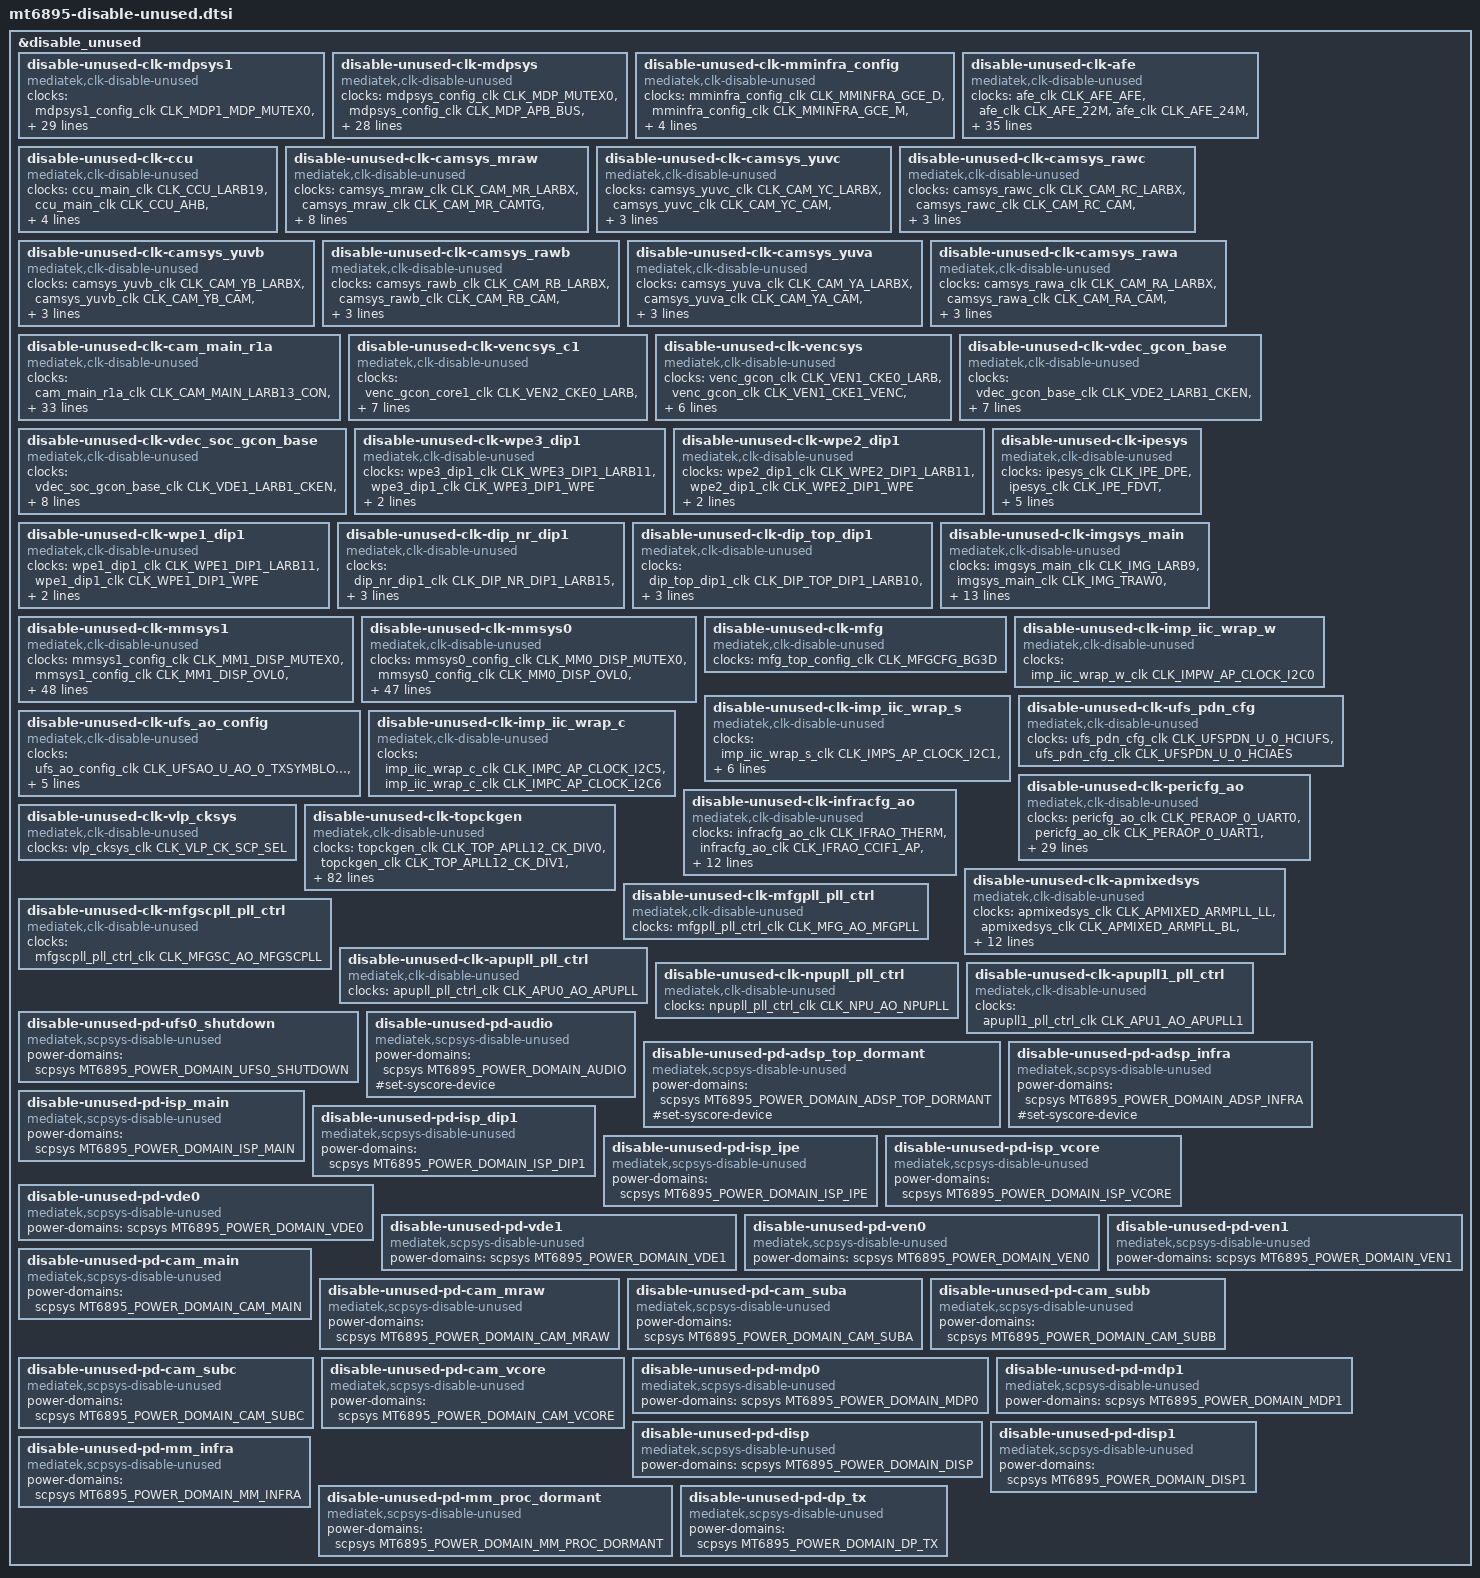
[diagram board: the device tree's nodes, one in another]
// SPDX-License-Identifier: (GPL-2.0 OR MIT)
/*
 * Copyright (C) 2021 MediaTek Inc.
 * Author: Ren-Ting Wang <ren-ting.wang@mediatek.com>
 */

&disable_unused {
	status = "okay";
	disable-unused-clk-mdpsys1 {
		compatible = "mediatek,clk-disable-unused";
		clocks =
			<&mdpsys1_config_clk CLK_MDP1_MDP_MUTEX0>,
			<&mdpsys1_config_clk CLK_MDP1_APB_BUS>,
			<&mdpsys1_config_clk CLK_MDP1_SMI0>,
			<&mdpsys1_config_clk CLK_MDP1_MDP_RDMA0>,
			<&mdpsys1_config_clk CLK_MDP1_MDP_FG0>,
			<&mdpsys1_config_clk CLK_MDP1_MDP_HDR0>,
			<&mdpsys1_config_clk CLK_MDP1_MDP_AAL0>,
			<&mdpsys1_config_clk CLK_MDP1_MDP_RSZ0>,
			<&mdpsys1_config_clk CLK_MDP1_MDP_TDSHP0>,
			<&mdpsys1_config_clk CLK_MDP1_MDP_COLOR0>,
			<&mdpsys1_config_clk CLK_MDP1_MDP_WROT0>,
			<&mdpsys1_config_clk CLK_MDP1_MDP_FAKE_ENG0>,
			<&mdpsys1_config_clk CLK_MDP1_MDP_DLI_ASYNC0>,
			<&mdpsys1_config_clk CLK_MDP1_MDP_DLI_ASYNC1>,
			<&mdpsys1_config_clk CLK_MDP1_MDP_RDMA1>,
			<&mdpsys1_config_clk CLK_MDP1_MDP_FG1>,
			<&mdpsys1_config_clk CLK_MDP1_MDP_HDR1>,
			<&mdpsys1_config_clk CLK_MDP1_MDP_AAL1>,
			<&mdpsys1_config_clk CLK_MDP1_MDP_RSZ1>,
			<&mdpsys1_config_clk CLK_MDP1_MDP_TDSHP1>,
			<&mdpsys1_config_clk CLK_MDP1_MDP_COLOR1>,
			<&mdpsys1_config_clk CLK_MDP1_MDP_WROT1>,
			<&mdpsys1_config_clk CLK_MDP1_MDP_RSZ2>,
			<&mdpsys1_config_clk CLK_MDP1_MDP_WROT2>,
			<&mdpsys1_config_clk CLK_MDP1_MDP_DLO_ASYNC0>,
			<&mdpsys1_config_clk CLK_MDP1_MDP_RSZ3>,
			<&mdpsys1_config_clk CLK_MDP1_MDP_WROT3>,
			<&mdpsys1_config_clk CLK_MDP1_MDP_DLO_ASYNC1>,
			<&mdpsys1_config_clk CLK_MDP1_HRE_TOP_MDPSYS>;
			power-domains = <&scpsys MT6895_POWER_DOMAIN_MDP1>;
	};

	disable-unused-clk-mdpsys {
		compatible = "mediatek,clk-disable-unused";
		clocks =
			<&mdpsys_config_clk CLK_MDP_MUTEX0>,
			<&mdpsys_config_clk CLK_MDP_APB_BUS>,
			<&mdpsys_config_clk CLK_MDP_SMI0>,
			<&mdpsys_config_clk CLK_MDP_RDMA0>,
			<&mdpsys_config_clk CLK_MDP_FG0>,
			<&mdpsys_config_clk CLK_MDP_HDR0>,
			<&mdpsys_config_clk CLK_MDP_AAL0>,
			<&mdpsys_config_clk CLK_MDP_RSZ0>,
			<&mdpsys_config_clk CLK_MDP_TDSHP0>,
			<&mdpsys_config_clk CLK_MDP_COLOR0>,
			<&mdpsys_config_clk CLK_MDP_WROT0>,
			<&mdpsys_config_clk CLK_MDP_FAKE_ENG0>,
			<&mdpsys_config_clk CLK_MDP_DLI_ASYNC0>,
			<&mdpsys_config_clk CLK_MDP_DLI_ASYNC1>,
			<&mdpsys_config_clk CLK_MDP_RDMA1>,
			<&mdpsys_config_clk CLK_MDP_FG1>,
			<&mdpsys_config_clk CLK_MDP_HDR1>,
			<&mdpsys_config_clk CLK_MDP_AAL1>,
			<&mdpsys_config_clk CLK_MDP_RSZ1>,
			<&mdpsys_config_clk CLK_MDP_TDSHP1>,
			<&mdpsys_config_clk CLK_MDP_COLOR1>,
			<&mdpsys_config_clk CLK_MDP_WROT1>,
			<&mdpsys_config_clk CLK_MDP_RSZ2>,
			<&mdpsys_config_clk CLK_MDP_WROT2>,
			<&mdpsys_config_clk CLK_MDP_DLO_ASYNC0>,
			<&mdpsys_config_clk CLK_MDP_RSZ3>,
			<&mdpsys_config_clk CLK_MDP_WROT3>,
			<&mdpsys_config_clk CLK_MDP_DLO_ASYNC1>,
			<&mdpsys_config_clk CLK_MDP_HRE_TOP_MDPSYS>;
			power-domains = <&scpsys MT6895_POWER_DOMAIN_MDP0>;
	};

	disable-unused-clk-mminfra_config {
		compatible = "mediatek,clk-disable-unused";
		clocks =
			<&mminfra_config_clk CLK_MMINFRA_GCE_D>,
			<&mminfra_config_clk CLK_MMINFRA_GCE_M>,
			<&mminfra_config_clk CLK_MMINFRA_SMI>,
			<&mminfra_config_clk CLK_MMINFRA_GCE_26M>;
			power-domains = <&scpsys MT6895_POWER_DOMAIN_MM_INFRA>;
	};

	disable-unused-clk-afe {
		compatible = "mediatek,clk-disable-unused";
		clocks =
			<&afe_clk CLK_AFE_AFE>,
			<&afe_clk CLK_AFE_22M>,
			<&afe_clk CLK_AFE_24M>,
			<&afe_clk CLK_AFE_APLL2_TUNER>,
			<&afe_clk CLK_AFE_APLL_TUNER>,
			<&afe_clk CLK_AFE_TDM>,
			<&afe_clk CLK_AFE_ADC>,
			<&afe_clk CLK_AFE_DAC>,
			<&afe_clk CLK_AFE_DAC_PREDIS>,
			<&afe_clk CLK_AFE_TML>,
			<&afe_clk CLK_AFE_NLE>,
			<&afe_clk CLK_AFE_GENERAL3_ASRC>,
			<&afe_clk CLK_AFE_CONNSYS_I2S_ASRC>,
			<&afe_clk CLK_AFE_GENERAL1_ASRC>,
			<&afe_clk CLK_AFE_GENERAL2_ASRC>,
			<&afe_clk CLK_AFE_DAC_HIRES>,
			<&afe_clk CLK_AFE_ADC_HIRES>,
			<&afe_clk CLK_AFE_ADC_HIRES_TML>,
			<&afe_clk CLK_AFE_ADDA6_ADC>,
			<&afe_clk CLK_AFE_ADDA6_ADC_HIRES>,
			<&afe_clk CLK_AFE_3RD_DAC>,
			<&afe_clk CLK_AFE_3RD_DAC_PREDIS>,
			<&afe_clk CLK_AFE_3RD_DAC_TML>,
			<&afe_clk CLK_AFE_3RD_DAC_HIRES>,
			<&afe_clk CLK_AFE_I2S5_BCLK>,
			<&afe_clk CLK_AFE_I2S6_BCLK>,
			<&afe_clk CLK_AFE_I2S7_BCLK>,
			<&afe_clk CLK_AFE_I2S8_BCLK>,
			<&afe_clk CLK_AFE_I2S9_BCLK>,
			<&afe_clk CLK_AFE_ETDM_IN0_BCLK>,
			<&afe_clk CLK_AFE_ETDM_OUT0_BCLK>,
			<&afe_clk CLK_AFE_I2S1_BCLK>,
			<&afe_clk CLK_AFE_I2S2_BCLK>,
			<&afe_clk CLK_AFE_I2S3_BCLK>,
			<&afe_clk CLK_AFE_I2S4_BCLK>,
			<&afe_clk CLK_AFE_ETDM_IN1_BCLK>,
			<&afe_clk CLK_AFE_ETDM_OUT1_BCLK>;
			power-domains = <&scpsys MT6895_POWER_DOMAIN_AUDIO>;
			#set-syscore-device;
	};

	disable-unused-clk-ccu {
		compatible = "mediatek,clk-disable-unused";
		clocks =
			<&ccu_main_clk CLK_CCU_LARB19>,
			<&ccu_main_clk CLK_CCU_AHB>,
			<&ccu_main_clk CLK_CCUSYS_CCU0>,
			<&ccu_main_clk CLK_CCUSYS_CCU1>;
			power-domains = <&scpsys MT6895_POWER_DOMAIN_CAM_MAIN>;
	};

	disable-unused-clk-camsys_mraw {
		compatible = "mediatek,clk-disable-unused";
		clocks =
			<&camsys_mraw_clk CLK_CAM_MR_LARBX>,
			<&camsys_mraw_clk CLK_CAM_MR_CAMTG>,
			<&camsys_mraw_clk CLK_CAM_MR_MRAW0>,
			<&camsys_mraw_clk CLK_CAM_MR_MRAW1>,
			<&camsys_mraw_clk CLK_CAM_MR_MRAW2>,
			<&camsys_mraw_clk CLK_CAM_MR_MRAW3>,
			<&camsys_mraw_clk CLK_CAM_MR_PDA0>,
			<&camsys_mraw_clk CLK_CAM_MR_PDA1>;
			power-domains = <&scpsys MT6895_POWER_DOMAIN_CAM_MRAW>;
	};

	disable-unused-clk-camsys_yuvc {
		compatible = "mediatek,clk-disable-unused";
		clocks =
			<&camsys_yuvc_clk CLK_CAM_YC_LARBX>,
			<&camsys_yuvc_clk CLK_CAM_YC_CAM>,
			<&camsys_yuvc_clk CLK_CAM_YC_CAMTG>;
			power-domains = <&scpsys MT6895_POWER_DOMAIN_CAM_SUBC>;
	};

	disable-unused-clk-camsys_rawc {
		compatible = "mediatek,clk-disable-unused";
		clocks =
			<&camsys_rawc_clk CLK_CAM_RC_LARBX>,
			<&camsys_rawc_clk CLK_CAM_RC_CAM>,
			<&camsys_rawc_clk CLK_CAM_RC_CAMTG>;
			power-domains = <&scpsys MT6895_POWER_DOMAIN_CAM_SUBC>;
	};

	disable-unused-clk-camsys_yuvb {
		compatible = "mediatek,clk-disable-unused";
		clocks =
			<&camsys_yuvb_clk CLK_CAM_YB_LARBX>,
			<&camsys_yuvb_clk CLK_CAM_YB_CAM>,
			<&camsys_yuvb_clk CLK_CAM_YB_CAMTG>;
			power-domains = <&scpsys MT6895_POWER_DOMAIN_CAM_SUBB>;
	};

	disable-unused-clk-camsys_rawb {
		compatible = "mediatek,clk-disable-unused";
		clocks =
			<&camsys_rawb_clk CLK_CAM_RB_LARBX>,
			<&camsys_rawb_clk CLK_CAM_RB_CAM>,
			<&camsys_rawb_clk CLK_CAM_RB_CAMTG>;
			power-domains = <&scpsys MT6895_POWER_DOMAIN_CAM_SUBB>;
	};

	disable-unused-clk-camsys_yuva {
		compatible = "mediatek,clk-disable-unused";
		clocks =
			<&camsys_yuva_clk CLK_CAM_YA_LARBX>,
			<&camsys_yuva_clk CLK_CAM_YA_CAM>,
			<&camsys_yuva_clk CLK_CAM_YA_CAMTG>;
			power-domains = <&scpsys MT6895_POWER_DOMAIN_CAM_SUBA>;
	};

	disable-unused-clk-camsys_rawa {
		compatible = "mediatek,clk-disable-unused";
		clocks =
			<&camsys_rawa_clk CLK_CAM_RA_LARBX>,
			<&camsys_rawa_clk CLK_CAM_RA_CAM>,
			<&camsys_rawa_clk CLK_CAM_RA_CAMTG>;
			power-domains = <&scpsys MT6895_POWER_DOMAIN_CAM_SUBA>;
	};

	disable-unused-clk-cam_main_r1a {
		compatible = "mediatek,clk-disable-unused";
		clocks =
			<&cam_main_r1a_clk CLK_CAM_MAIN_LARB13_CON>,
			<&cam_main_r1a_clk CLK_CAM_MAIN_LARB14_CON>,
			<&cam_main_r1a_clk CLK_CAM_MAIN_CAM_CON>,
			<&cam_main_r1a_clk CLK_CAM_MAIN_CAM_SUBA_CON>,
			<&cam_main_r1a_clk CLK_CAM_MAIN_CAM_SUBB_CON>,
			<&cam_main_r1a_clk CLK_CAM_MAIN_CAM_SUBC_CON>,
			<&cam_main_r1a_clk CLK_CAM_MAIN_CAM_MRAW_CON>,
			<&cam_main_r1a_clk CLK_CAM_MAIN_CAMTG_CON>,
			<&cam_main_r1a_clk CLK_CAM_MAIN_SENINF_CON>,
			<&cam_main_r1a_clk CLK_CAM_MAIN_GCAMSVA_CON>,
			<&cam_main_r1a_clk CLK_CAM_MAIN_GCAMSVB_CON>,
			<&cam_main_r1a_clk CLK_CAM_MAIN_GCAMSVC_CON>,
			<&cam_main_r1a_clk CLK_CAM_MAIN_GCAMSVD_CON>,
			<&cam_main_r1a_clk CLK_CAM_MAIN_GCAMSVE_CON>,
			<&cam_main_r1a_clk CLK_CAM_MAIN_GCAMSVF_CON>,
			<&cam_main_r1a_clk CLK_CAM_MAIN_GCAMSVG_CON>,
			<&cam_main_r1a_clk CLK_CAM_MAIN_GCAMSVH_CON>,
			<&cam_main_r1a_clk CLK_CAM_MAIN_GCAMSVI_CON>,
			<&cam_main_r1a_clk CLK_CAM_MAIN_GCAMSVJ_CON>,
			<&cam_main_r1a_clk CLK_CAM_MAIN_CAMSV_TOP_CON>,
			<&cam_main_r1a_clk CLK_CAM_MAIN_CAMSV_CQ_A_CON>,
			<&cam_main_r1a_clk CLK_CAM_MAIN_CAMSV_CQ_B_CON>,
			<&cam_main_r1a_clk CLK_CAM_MAIN_CAMSV_CQ_C_CON>,
			<&cam_main_r1a_clk CLK_CAM_MAIN_ADL_CON>,
			<&cam_main_r1a_clk CLK_CAM_MAIN_ASG_CON>,
			<&cam_main_r1a_clk CLK_CAM_MAIN_PDA0_CON>,
			<&cam_main_r1a_clk CLK_CAM_MAIN_PDA1_CON>,
			<&cam_main_r1a_clk CLK_CAM_MAIN_PDA2_CON>,
			<&cam_main_r1a_clk CLK_CAM_MAIN_FAKE_ENG_CON>,
			<&cam_main_r1a_clk CLK_CAM_MAIN_CAM2MM0_GALS_CON>,
			<&cam_main_r1a_clk CLK_CAM_MAIN_CAM2MM1_GALS_CON>,
			<&cam_main_r1a_clk CLK_CAM_MAIN_CAM2SYS_GALS_CON>;
			power-domains = <&scpsys MT6895_POWER_DOMAIN_CAM_MAIN>;
	};

	disable-unused-clk-vencsys_c1 {
		compatible = "mediatek,clk-disable-unused";
		clocks =
			<&venc_gcon_core1_clk CLK_VEN2_CKE0_LARB>,
			<&venc_gcon_core1_clk CLK_VEN2_CKE1_VENC>,
			<&venc_gcon_core1_clk CLK_VEN2_CKE2_JPGENC>,
			<&venc_gcon_core1_clk CLK_VEN2_CKE3_JPGDEC>,
			<&venc_gcon_core1_clk CLK_VEN2_CKE4_JPGDEC_C1>,
			<&venc_gcon_core1_clk CLK_VEN2_CKE5_GALS>,
			<&venc_gcon_core1_clk CLK_VEN2_CKE6_GALS_SRAM>;
			power-domains = <&scpsys MT6895_POWER_DOMAIN_VEN1>;
	};

	disable-unused-clk-vencsys {
		compatible = "mediatek,clk-disable-unused";
		clocks =
			<&venc_gcon_clk CLK_VEN1_CKE0_LARB>,
			<&venc_gcon_clk CLK_VEN1_CKE1_VENC>,
			<&venc_gcon_clk CLK_VEN1_CKE2_JPGENC>,
			<&venc_gcon_clk CLK_VEN1_CKE3_JPGDEC>,
			<&venc_gcon_clk CLK_VEN1_CKE4_JPGDEC_C1>,
			<&venc_gcon_clk CLK_VEN1_CKE5_GALS>,
			<&venc_gcon_clk CLK_VEN1_CKE6_GALS_SRAM>;
			power-domains = <&scpsys MT6895_POWER_DOMAIN_VEN0>;
	};

	disable-unused-clk-vdec_gcon_base {
		compatible = "mediatek,clk-disable-unused";
		clocks =
			<&vdec_gcon_base_clk CLK_VDE2_LARB1_CKEN>,
			<&vdec_gcon_base_clk CLK_VDE2_LAT_CKEN>,
			<&vdec_gcon_base_clk CLK_VDE2_LAT_ACTIVE>,
			<&vdec_gcon_base_clk CLK_VDE2_LAT_CKEN_ENG>,
			<&vdec_gcon_base_clk CLK_VDE2_VDEC_CKEN>,
			<&vdec_gcon_base_clk CLK_VDE2_VDEC_ACTIVE>,
			<&vdec_gcon_base_clk CLK_VDE2_VDEC_CKEN_ENG>;
			power-domains = <&scpsys MT6895_POWER_DOMAIN_VDE1>;
	};

	disable-unused-clk-vdec_soc_gcon_base {
		compatible = "mediatek,clk-disable-unused";
		clocks =
			<&vdec_soc_gcon_base_clk CLK_VDE1_LARB1_CKEN>,
			<&vdec_soc_gcon_base_clk CLK_VDE1_LAT_CKEN>,
			<&vdec_soc_gcon_base_clk CLK_VDE1_LAT_ACTIVE>,
			<&vdec_soc_gcon_base_clk CLK_VDE1_LAT_CKEN_ENG>,
			<&vdec_soc_gcon_base_clk CLK_VDE1_MINI_MDP_CKEN_CFG_RG>,
			<&vdec_soc_gcon_base_clk CLK_VDE1_VDEC_CKEN>,
			<&vdec_soc_gcon_base_clk CLK_VDE1_VDEC_ACTIVE>,
			<&vdec_soc_gcon_base_clk CLK_VDE1_VDEC_CKEN_ENG>;
			power-domains = <&scpsys MT6895_POWER_DOMAIN_VDE0>;
	};

	disable-unused-clk-wpe3_dip1 {
		compatible = "mediatek,clk-disable-unused";
		clocks =
			<&wpe3_dip1_clk CLK_WPE3_DIP1_LARB11>,
			<&wpe3_dip1_clk CLK_WPE3_DIP1_WPE>;
			power-domains = <&scpsys MT6895_POWER_DOMAIN_ISP_DIP1>;
	};

	disable-unused-clk-wpe2_dip1 {
		compatible = "mediatek,clk-disable-unused";
		clocks =
			<&wpe2_dip1_clk CLK_WPE2_DIP1_LARB11>,
			<&wpe2_dip1_clk CLK_WPE2_DIP1_WPE>;
			power-domains = <&scpsys MT6895_POWER_DOMAIN_ISP_DIP1>;
	};

	disable-unused-clk-ipesys {
		compatible = "mediatek,clk-disable-unused";
		clocks =
			<&ipesys_clk CLK_IPE_DPE>,
			<&ipesys_clk CLK_IPE_FDVT>,
			<&ipesys_clk CLK_IPE_ME>,
			<&ipesys_clk CLK_IPESYS_TOP>,
			<&ipesys_clk CLK_IPE_SMI_LARB12>;
			power-domains = <&scpsys MT6895_POWER_DOMAIN_ISP_IPE>;
	};

	disable-unused-clk-wpe1_dip1 {
		compatible = "mediatek,clk-disable-unused";
		clocks =
			<&wpe1_dip1_clk CLK_WPE1_DIP1_LARB11>,
			<&wpe1_dip1_clk CLK_WPE1_DIP1_WPE>;
			power-domains = <&scpsys MT6895_POWER_DOMAIN_ISP_DIP1>;
	};

	disable-unused-clk-dip_nr_dip1 {
		compatible = "mediatek,clk-disable-unused";
		clocks =
			<&dip_nr_dip1_clk CLK_DIP_NR_DIP1_LARB15>,
			<&dip_nr_dip1_clk CLK_DIP_NR_DIP1_DIP_NR>;
			power-domains = <&scpsys MT6895_POWER_DOMAIN_ISP_DIP1>;
	};

	disable-unused-clk-dip_top_dip1 {
		compatible = "mediatek,clk-disable-unused";
		clocks =
			<&dip_top_dip1_clk CLK_DIP_TOP_DIP1_LARB10>,
			<&dip_top_dip1_clk CLK_DIP_TOP_DIP1_DIP_TOP>;
			power-domains = <&scpsys MT6895_POWER_DOMAIN_ISP_DIP1>;
	};

	disable-unused-clk-imgsys_main {
		compatible = "mediatek,clk-disable-unused";
		clocks =
			<&imgsys_main_clk CLK_IMG_LARB9>,
			<&imgsys_main_clk CLK_IMG_TRAW0>,
			<&imgsys_main_clk CLK_IMG_TRAW1>,
			<&imgsys_main_clk CLK_IMG_VCORE_GALS>,
			<&imgsys_main_clk CLK_IMG_DIP0>,
			<&imgsys_main_clk CLK_IMG_WPE0>,
			<&imgsys_main_clk CLK_IMG_IPE>,
			<&imgsys_main_clk CLK_IMG_WPE1>,
			<&imgsys_main_clk CLK_IMG_WPE2>,
			<&imgsys_main_clk CLK_IMG_ADL_LARB>,
			<&imgsys_main_clk CLK_IMG_ADL_TOP0>,
			<&imgsys_main_clk CLK_IMG_ADL_TOP1>,
			<&imgsys_main_clk CLK_IMG_GALS>;
			power-domains = <&scpsys MT6895_POWER_DOMAIN_ISP_MAIN>;
	};

	disable-unused-clk-mmsys1 {
		compatible = "mediatek,clk-disable-unused";
		clocks =
			<&mmsys1_config_clk CLK_MM1_DISP_MUTEX0>,
			<&mmsys1_config_clk CLK_MM1_DISP_OVL0>,
			<&mmsys1_config_clk CLK_MM1_DISP_MERGE0>,
			<&mmsys1_config_clk CLK_MM1_DISP_FAKE_ENG0>,
			<&mmsys1_config_clk CLK_MM1_INLINEROT0>,
			<&mmsys1_config_clk CLK_MM1_DISP_WDMA0>,
			<&mmsys1_config_clk CLK_MM1_DISP_FAKE_ENG1>,
			<&mmsys1_config_clk CLK_MM1_DISP_DPI0>,
			<&mmsys1_config_clk CLK_MM1_DISP_OVL0_2L_NW>,
			<&mmsys1_config_clk CLK_MM1_DISP_RDMA0>,
			<&mmsys1_config_clk CLK_MM1_DISP_RDMA1>,
			<&mmsys1_config_clk CLK_MM1_DISP_DLI_ASYNC0>,
			<&mmsys1_config_clk CLK_MM1_DISP_DLI_ASYNC1>,
			<&mmsys1_config_clk CLK_MM1_DISP_DLI_ASYNC2>,
			<&mmsys1_config_clk CLK_MM1_DISP_DLO_ASYNC0>,
			<&mmsys1_config_clk CLK_MM1_DISP_DLO_ASYNC1>,
			<&mmsys1_config_clk CLK_MM1_DISP_DLO_ASYNC2>,
			<&mmsys1_config_clk CLK_MM1_DISP_RSZ0>,
			<&mmsys1_config_clk CLK_MM1_DISP_COLOR0>,
			<&mmsys1_config_clk CLK_MM1_DISP_CCORR0>,
			<&mmsys1_config_clk CLK_MM1_DISP_CCORR1>,
			<&mmsys1_config_clk CLK_MM1_DISP_AAL0>,
			<&mmsys1_config_clk CLK_MM1_DISP_GAMMA0>,
			<&mmsys1_config_clk CLK_MM1_DISP_POSTMASK0>,
			<&mmsys1_config_clk CLK_MM1_DISP_DITHER0>,
			<&mmsys1_config_clk CLK_MM1_DISP_CM0>,
			<&mmsys1_config_clk CLK_MM1_DISP_SPR0>,
			<&mmsys1_config_clk CLK_MM1_DISP_DSC_WRAP0>,
			<&mmsys1_config_clk CLK_MM1_FMM_DISP_DSI0>,
			<&mmsys1_config_clk CLK_MM1_DISP_UFBC_WDMA0>,
			<&mmsys1_config_clk CLK_MM1_DISP_WDMA1>,
			<&mmsys1_config_clk CLK_MM1_FMM_DISP_DP_INTF0>,
			<&mmsys1_config_clk CLK_MM1_APB_BUS>,
			<&mmsys1_config_clk CLK_MM1_DISP_TDSHP0>,
			<&mmsys1_config_clk CLK_MM1_DISP_C3D0>,
			<&mmsys1_config_clk CLK_MM1_DISP_Y2R0>,
			<&mmsys1_config_clk CLK_MM1_MDP_AAL0>,
			<&mmsys1_config_clk CLK_MM1_DISP_CHIST0>,
			<&mmsys1_config_clk CLK_MM1_DISP_CHIST1>,
			<&mmsys1_config_clk CLK_MM1_DISP_OVL0_2L>,
			<&mmsys1_config_clk CLK_MM1_DISP_DLI_ASYNC3>,
			<&mmsys1_config_clk CLK_MM1_DISP_DLO_ASYNC3>,
			<&mmsys1_config_clk CLK_MM1_DISP_OVL1_2L>,
			<&mmsys1_config_clk CLK_MM1_DISP_OVL1_2L_NW>,
			<&mmsys1_config_clk CLK_MM1_SMI_COMMON>,
			<&mmsys1_config_clk CLK_MM1_DISP_DSI>,
			<&mmsys1_config_clk CLK_MM1_DISP_DP_INTF0>,
			<&mmsys1_config_clk CLK_MM1_SIG_EMI>;
			power-domains = <&scpsys MT6895_POWER_DOMAIN_DISP1>;
	};

	disable-unused-clk-mmsys0 {
		compatible = "mediatek,clk-disable-unused";
		clocks =
			<&mmsys0_config_clk CLK_MM0_DISP_MUTEX0>,
			<&mmsys0_config_clk CLK_MM0_DISP_OVL0>,
			<&mmsys0_config_clk CLK_MM0_DISP_MERGE0>,
			<&mmsys0_config_clk CLK_MM0_DISP_FAKE_ENG0>,
			<&mmsys0_config_clk CLK_MM0_INLINEROT0>,
			<&mmsys0_config_clk CLK_MM0_DISP_WDMA0>,
			<&mmsys0_config_clk CLK_MM0_DISP_FAKE_ENG1>,
			<&mmsys0_config_clk CLK_MM0_DISP_DPI0>,
			<&mmsys0_config_clk CLK_MM0_DISP_OVL0_2L_NW>,
			<&mmsys0_config_clk CLK_MM0_DISP_RDMA0>,
			<&mmsys0_config_clk CLK_MM0_DISP_RDMA1>,
			<&mmsys0_config_clk CLK_MM0_DISP_DLI_ASYNC0>,
			<&mmsys0_config_clk CLK_MM0_DISP_DLI_ASYNC1>,
			<&mmsys0_config_clk CLK_MM0_DISP_DLI_ASYNC2>,
			<&mmsys0_config_clk CLK_MM0_DISP_DLO_ASYNC0>,
			<&mmsys0_config_clk CLK_MM0_DISP_DLO_ASYNC1>,
			<&mmsys0_config_clk CLK_MM0_DISP_DLO_ASYNC2>,
			<&mmsys0_config_clk CLK_MM0_DISP_RSZ0>,
			<&mmsys0_config_clk CLK_MM0_DISP_COLOR0>,
			<&mmsys0_config_clk CLK_MM0_DISP_CCORR0>,
			<&mmsys0_config_clk CLK_MM0_DISP_CCORR1>,
			<&mmsys0_config_clk CLK_MM0_DISP_AAL0>,
			<&mmsys0_config_clk CLK_MM0_DISP_GAMMA0>,
			<&mmsys0_config_clk CLK_MM0_DISP_POSTMASK0>,
			<&mmsys0_config_clk CLK_MM0_DISP_DITHER0>,
			<&mmsys0_config_clk CLK_MM0_DISP_CM0>,
			<&mmsys0_config_clk CLK_MM0_DISP_SPR0>,
			<&mmsys0_config_clk CLK_MM0_DISP_DSC_WRAP0>,
			<&mmsys0_config_clk CLK_MM0_FMM_DISP_DSI0>,
			<&mmsys0_config_clk CLK_MM0_DISP_UFBC_WDMA0>,
			<&mmsys0_config_clk CLK_MM0_DISP_WDMA1>,
			<&mmsys0_config_clk CLK_MM0_FMM_DISP_DP_INTF0>,
			<&mmsys0_config_clk CLK_MM0_APB_BUS>,
			<&mmsys0_config_clk CLK_MM0_DISP_TDSHP0>,
			<&mmsys0_config_clk CLK_MM0_DISP_C3D0>,
			<&mmsys0_config_clk CLK_MM0_DISP_Y2R0>,
			<&mmsys0_config_clk CLK_MM0_MDP_AAL0>,
			<&mmsys0_config_clk CLK_MM0_DISP_CHIST0>,
			<&mmsys0_config_clk CLK_MM0_DISP_CHIST1>,
			<&mmsys0_config_clk CLK_MM0_DISP_OVL0_2L>,
			<&mmsys0_config_clk CLK_MM0_DISP_DLI_ASYNC3>,
			<&mmsys0_config_clk CLK_MM0_DISP_DLO_ASYNC3>,
			<&mmsys0_config_clk CLK_MM0_DISP_OVL1_2L>,
			<&mmsys0_config_clk CLK_MM0_DISP_OVL1_2L_NW>,
			<&mmsys0_config_clk CLK_MM0_SMI_COMMON>,
			<&mmsys0_config_clk CLK_MM0_DISP_DSI>,
			<&mmsys0_config_clk CLK_MM0_DISP_DP_INTF0>,
			<&mmsys0_config_clk CLK_MM0_SIG_EMI>;
			power-domains = <&scpsys MT6895_POWER_DOMAIN_DISP>;
	};

	disable-unused-clk-mfg {
		compatible = "mediatek,clk-disable-unused";
		clocks =
			<&mfg_top_config_clk CLK_MFGCFG_BG3D>;
	};

	disable-unused-clk-imp_iic_wrap_w {
		compatible = "mediatek,clk-disable-unused";
		clocks =
			<&imp_iic_wrap_w_clk CLK_IMPW_AP_CLOCK_I2C0>;
	};

	disable-unused-clk-imp_iic_wrap_s {
		compatible = "mediatek,clk-disable-unused";
		clocks =
			<&imp_iic_wrap_s_clk CLK_IMPS_AP_CLOCK_I2C1>,
			<&imp_iic_wrap_s_clk CLK_IMPS_AP_CLOCK_I2C2>,
			<&imp_iic_wrap_s_clk CLK_IMPS_AP_CLOCK_I2C3>,
			<&imp_iic_wrap_s_clk CLK_IMPS_AP_CLOCK_I2C4>,
			<&imp_iic_wrap_s_clk CLK_IMPS_AP_CLOCK_I2C7>,
			<&imp_iic_wrap_s_clk CLK_IMPS_AP_CLOCK_I2C8>,
			<&imp_iic_wrap_s_clk CLK_IMPS_AP_CLOCK_I2C9>;
	};

	disable-unused-clk-ufs_pdn_cfg {
		compatible = "mediatek,clk-disable-unused";
		clocks =
			<&ufs_pdn_cfg_clk CLK_UFSPDN_U_0_HCIUFS>,
			<&ufs_pdn_cfg_clk CLK_UFSPDN_U_0_HCIAES>;
	};

	disable-unused-clk-ufs_ao_config {
		compatible = "mediatek,clk-disable-unused";
		clocks =
			<&ufs_ao_config_clk CLK_UFSAO_U_AO_0_TXSYMBLOCLK>,
			<&ufs_ao_config_clk CLK_UFSAO_U_AO_0_RXSYMBLOCLK0>,
			<&ufs_ao_config_clk CLK_UFSAO_U_AO_0_RXSYMBLOCLK1>,
			<&ufs_ao_config_clk CLK_UFSAO_U_AO_0_SYSCLK>,
			<&ufs_ao_config_clk CLK_UFSAO_U_AO_0_UMPSAP>,
			<&ufs_ao_config_clk CLK_UFSAO_U_AO_0_MMPSAP>;
	};

	disable-unused-clk-imp_iic_wrap_c {
		compatible = "mediatek,clk-disable-unused";
		clocks =
			<&imp_iic_wrap_c_clk CLK_IMPC_AP_CLOCK_I2C5>,
			<&imp_iic_wrap_c_clk CLK_IMPC_AP_CLOCK_I2C6>;
	};

	disable-unused-clk-pericfg_ao {
		compatible = "mediatek,clk-disable-unused";
		clocks =
			<&pericfg_ao_clk CLK_PERAOP_0_UART0>,
			<&pericfg_ao_clk CLK_PERAOP_0_UART1>,
			<&pericfg_ao_clk CLK_PERAOP_0_UART2>,
			<&pericfg_ao_clk CLK_PERAOP_0_PWM_HCLK>,
			<&pericfg_ao_clk CLK_PERAOP_0_PWM_BCLK>,
			<&pericfg_ao_clk CLK_PERAOP_0_PWM_FBCLK1>,
			<&pericfg_ao_clk CLK_PERAOP_0_PWM_FBCLK2>,
			<&pericfg_ao_clk CLK_PERAOP_0_PWM_FBCLK3>,
			<&pericfg_ao_clk CLK_PERAOP_0_PWM_FBCLK4>,
			<&pericfg_ao_clk CLK_PERAOP_0_BTIF>,
			<&pericfg_ao_clk CLK_PERAOP_0_DISP>,
			<&pericfg_ao_clk CLK_PERAOP_0_DISP_H>,
			<&pericfg_ao_clk CLK_PERAOP_0_SPI0_BCLK>,
			<&pericfg_ao_clk CLK_PERAOP_0_SPI1_BCLK>,
			<&pericfg_ao_clk CLK_PERAOP_0_SPI2_BCLK>,
			<&pericfg_ao_clk CLK_PERAOP_0_SPI3_BCLK>,
			<&pericfg_ao_clk CLK_PERAOP_0_SPI4_BCLK>,
			<&pericfg_ao_clk CLK_PERAOP_0_SPI5_BCLK>,
			<&pericfg_ao_clk CLK_PERAOP_0_SPI6_BCLK>,
			<&pericfg_ao_clk CLK_PERAOP_0_SPI7_BCLK>,
			<&pericfg_ao_clk CLK_PERAOP_1_DMA_BCLK>,
			<&pericfg_ao_clk CLK_PERAOP_1_USB_FRMC>,
			<&pericfg_ao_clk CLK_PERAOP_1_USB_SYS>,
			<&pericfg_ao_clk CLK_PERAOP_1_USB_XHCI>,
			<&pericfg_ao_clk CLK_PERAOP_1_USB1P_FRMC>,
			<&pericfg_ao_clk CLK_PERAOP_1_USB1P_SYS>,
			<&pericfg_ao_clk CLK_PERAOP_1_USB1P_XHCI>,
			<&pericfg_ao_clk CLK_PERAOP_1_MSDC1>,
			<&pericfg_ao_clk CLK_PERAOP_1_MSDC1_HCLK>,
			<&pericfg_ao_clk CLK_PERAOP_1_MSDC2>,
			<&pericfg_ao_clk CLK_PERAOP_1_MSDC2_HCLK>;
	};

	disable-unused-clk-infracfg_ao {
		compatible = "mediatek,clk-disable-unused";
		clocks =
			<&infracfg_ao_clk CLK_IFRAO_THERM>,
			<&infracfg_ao_clk CLK_IFRAO_CCIF1_AP>,
			<&infracfg_ao_clk CLK_IFRAO_CCIF1_MD>,
			<&infracfg_ao_clk CLK_IFRAO_CCIF_AP>,
			<&infracfg_ao_clk CLK_IFRAO_CCIF_MD>,
			<&infracfg_ao_clk CLK_IFRAO_CLDMA_BCLK>,
			<&infracfg_ao_clk CLK_IFRAO_CQ_DMA>,
			<&infracfg_ao_clk CLK_IFRAO_CCIF5_MD>,
			<&infracfg_ao_clk CLK_IFRAO_CCIF2_AP>,
			<&infracfg_ao_clk CLK_IFRAO_CCIF2_MD>,
			<&infracfg_ao_clk CLK_IFRAO_FBIST2FPC>,
			<&infracfg_ao_clk CLK_IFRAO_DPMAIF_MAIN>,
			<&infracfg_ao_clk CLK_IFRAO_CCIF4_MD>,
			<&infracfg_ao_clk CLK_IFRAO_RG_MMW_DPMAIF26M_CK>;
	};

	disable-unused-clk-vlp_cksys {
		compatible = "mediatek,clk-disable-unused";
		clocks =
			<&vlp_cksys_clk CLK_VLP_CK_SCP_SEL>;
	};

	disable-unused-clk-topckgen {
		compatible = "mediatek,clk-disable-unused";
		clocks =
			<&topckgen_clk CLK_TOP_APLL12_CK_DIV0>,
			<&topckgen_clk CLK_TOP_APLL12_CK_DIV1>,
			<&topckgen_clk CLK_TOP_APLL12_CK_DIV2>,
			<&topckgen_clk CLK_TOP_APLL12_CK_DIV3>,
			<&topckgen_clk CLK_TOP_APLL12_CK_DIV4>,
			<&topckgen_clk CLK_TOP_APLL12_CK_DIVB>,
			<&topckgen_clk CLK_TOP_APLL12_CK_DIV5>,
			<&topckgen_clk CLK_TOP_APLL12_CK_DIV6>,
			<&topckgen_clk CLK_TOP_APLL12_CK_DIV7>,
			<&topckgen_clk CLK_TOP_APLL12_CK_DIV8>,
			<&topckgen_clk CLK_TOP_APLL12_CK_DIV9>,
			<&topckgen_clk CLK_TOP_DISP0_SEL>,
			<&topckgen_clk CLK_TOP_DISP1_SEL>,
			<&topckgen_clk CLK_TOP_MDP0_SEL>,
			<&topckgen_clk CLK_TOP_MDP1_SEL>,
			<&topckgen_clk CLK_TOP_MMINFRA_SEL>,
			<&topckgen_clk CLK_TOP_MMUP_SEL>,
			<&topckgen_clk CLK_TOP_DSP_SEL>,
			<&topckgen_clk CLK_TOP_DSP1_SEL>,
			<&topckgen_clk CLK_TOP_DSP2_SEL>,
			<&topckgen_clk CLK_TOP_DSP3_SEL>,
			<&topckgen_clk CLK_TOP_DSP4_SEL>,
			<&topckgen_clk CLK_TOP_DSP5_SEL>,
			<&topckgen_clk CLK_TOP_DSP6_SEL>,
			<&topckgen_clk CLK_TOP_DSP7_SEL>,
			<&topckgen_clk CLK_TOP_MFG_REF_SEL>,
			<&topckgen_clk CLK_TOP_MFGSC_REF_SEL>,
			<&topckgen_clk CLK_TOP_CAMTG_SEL>,
			<&topckgen_clk CLK_TOP_CAMTG2_SEL>,
			<&topckgen_clk CLK_TOP_CAMTG3_SEL>,
			<&topckgen_clk CLK_TOP_CAMTG4_SEL>,
			<&topckgen_clk CLK_TOP_CAMTG5_SEL>,
			<&topckgen_clk CLK_TOP_CAMTG6_SEL>,
			<&topckgen_clk CLK_TOP_CAMTG7_SEL>,
			<&topckgen_clk CLK_TOP_SPI_SEL>,
			<&topckgen_clk CLK_TOP_MSDC_MACRO_SEL>,
			<&topckgen_clk CLK_TOP_MSDC30_1_SEL>,
			<&topckgen_clk CLK_TOP_MSDC30_2_SEL>,
			<&topckgen_clk CLK_TOP_AUDIO_SEL>,
			<&topckgen_clk CLK_TOP_AUD_INTBUS_SEL>,
			<&topckgen_clk CLK_TOP_DP_SEL>,
			<&topckgen_clk CLK_TOP_DISP_PWM_SEL>,
			<&topckgen_clk CLK_TOP_USB_TOP_SEL>,
			<&topckgen_clk CLK_TOP_USB_XHCI_SEL>,
			<&topckgen_clk CLK_TOP_USB_TOP_1P_SEL>,
			<&topckgen_clk CLK_TOP_USB_XHCI_1P_SEL>,
			<&topckgen_clk CLK_TOP_I2C_SEL>,
			<&topckgen_clk CLK_TOP_SENINF_SEL>,
			<&topckgen_clk CLK_TOP_SENINF1_SEL>,
			<&topckgen_clk CLK_TOP_SENINF2_SEL>,
			<&topckgen_clk CLK_TOP_SENINF3_SEL>,
			<&topckgen_clk CLK_TOP_SENINF4_SEL>,
			<&topckgen_clk CLK_TOP_AUD_ENGEN1_SEL>,
			<&topckgen_clk CLK_TOP_AUD_ENGEN2_SEL>,
			<&topckgen_clk CLK_TOP_AES_UFSFDE_SEL>,
			<&topckgen_clk CLK_TOP_U_SEL>,
			<&topckgen_clk CLK_TOP_U_MBIST_SEL>,
			<&topckgen_clk CLK_TOP_PEXTP_MBIST_SEL>,
			<&topckgen_clk CLK_TOP_AUD_1_SEL>,
			<&topckgen_clk CLK_TOP_AUD_2_SEL>,
			<&topckgen_clk CLK_TOP_ADSP_SEL>,
			<&topckgen_clk CLK_TOP_VENC_SEL>,
			<&topckgen_clk CLK_TOP_VDEC_SEL>,
			<&topckgen_clk CLK_TOP_PWM_SEL>,
			<&topckgen_clk CLK_TOP_AUDIO_H_SEL>,
			<&topckgen_clk CLK_TOP_DSI_OCC_SEL>,
			<&topckgen_clk CLK_TOP_CCU_AHB_SEL>,
			<&topckgen_clk CLK_TOP_IMG1_SEL>,
			<&topckgen_clk CLK_TOP_IPE_SEL>,
			<&topckgen_clk CLK_TOP_CAM_SEL>,
			<&topckgen_clk CLK_TOP_CCUSYS_SEL>,
			<&topckgen_clk CLK_TOP_CAMTM_SEL>,
			<&topckgen_clk CLK_TOP_MFG_SEL_0_SEL>,
			<&topckgen_clk CLK_TOP_MFG_SEL_1_SEL>,
			<&topckgen_clk CLK_TOP_APLL_I2S0_MCK_SEL>,
			<&topckgen_clk CLK_TOP_APLL_I2S1_MCK_SEL>,
			<&topckgen_clk CLK_TOP_APLL_I2S2_MCK_SEL>,
			<&topckgen_clk CLK_TOP_APLL_I2S3_MCK_SEL>,
			<&topckgen_clk CLK_TOP_APLL_I2S4_MCK_SEL>,
			<&topckgen_clk CLK_TOP_APLL_I2S5_MCK_SEL>,
			<&topckgen_clk CLK_TOP_APLL_I2S6_MCK_SEL>,
			<&topckgen_clk CLK_TOP_APLL_I2S7_MCK_SEL>,
			<&topckgen_clk CLK_TOP_APLL_I2S8_MCK_SEL>,
			<&topckgen_clk CLK_TOP_APLL_I2S9_MCK_SEL>;
	};

	disable-unused-clk-apmixedsys {
		compatible = "mediatek,clk-disable-unused";
		clocks =
			<&apmixedsys_clk CLK_APMIXED_ARMPLL_LL>,
			<&apmixedsys_clk CLK_APMIXED_ARMPLL_BL>,
			<&apmixedsys_clk CLK_APMIXED_ARMPLL_B>,
			<&apmixedsys_clk CLK_APMIXED_CCIPLL>,
			<&apmixedsys_clk CLK_APMIXED_MAINPLL>,
			<&apmixedsys_clk CLK_APMIXED_UNIVPLL>,
			<&apmixedsys_clk CLK_APMIXED_MSDCPLL>,
			<&apmixedsys_clk CLK_APMIXED_MMPLL>,
			<&apmixedsys_clk CLK_APMIXED_ADSPPLL>,
			<&apmixedsys_clk CLK_APMIXED_TVDPLL>,
			<&apmixedsys_clk CLK_APMIXED_APLL1>,
			<&apmixedsys_clk CLK_APMIXED_APLL2>,
			<&apmixedsys_clk CLK_APMIXED_MPLL>,
			<&apmixedsys_clk CLK_APMIXED_IMGPLL>;
	};

	disable-unused-clk-mfgpll_pll_ctrl {
		compatible = "mediatek,clk-disable-unused";
		clocks =
			<&mfgpll_pll_ctrl_clk CLK_MFG_AO_MFGPLL>;
	};

	disable-unused-clk-mfgscpll_pll_ctrl {
		compatible = "mediatek,clk-disable-unused";
		clocks =
			<&mfgscpll_pll_ctrl_clk CLK_MFGSC_AO_MFGSCPLL>;
	};

	disable-unused-clk-apupll_pll_ctrl {
		compatible = "mediatek,clk-disable-unused";
		clocks =
			<&apupll_pll_ctrl_clk CLK_APU0_AO_APUPLL>;
	};

	disable-unused-clk-npupll_pll_ctrl {
		compatible = "mediatek,clk-disable-unused";
		clocks =
			<&npupll_pll_ctrl_clk CLK_NPU_AO_NPUPLL>;
	};

	disable-unused-clk-apupll1_pll_ctrl {
		compatible = "mediatek,clk-disable-unused";
		clocks =
			<&apupll1_pll_ctrl_clk CLK_APU1_AO_APUPLL1>;
	};

	disable-unused-pd-ufs0_shutdown {
		compatible = "mediatek,scpsys-disable-unused";
		power-domains = <&scpsys MT6895_POWER_DOMAIN_UFS0_SHUTDOWN>;
	};

	disable-unused-pd-audio {
		compatible = "mediatek,scpsys-disable-unused";
		power-domains = <&scpsys MT6895_POWER_DOMAIN_AUDIO>;
		#set-syscore-device;
	};

	disable-unused-pd-adsp_top_dormant {
		compatible = "mediatek,scpsys-disable-unused";
		power-domains = <&scpsys MT6895_POWER_DOMAIN_ADSP_TOP_DORMANT>;
		#set-syscore-device;
	};

	disable-unused-pd-adsp_infra {
		compatible = "mediatek,scpsys-disable-unused";
		power-domains = <&scpsys MT6895_POWER_DOMAIN_ADSP_INFRA>;
		#set-syscore-device;
	};

	disable-unused-pd-isp_main {
		compatible = "mediatek,scpsys-disable-unused";
		power-domains = <&scpsys MT6895_POWER_DOMAIN_ISP_MAIN>;
	};

	disable-unused-pd-isp_dip1 {
		compatible = "mediatek,scpsys-disable-unused";
		power-domains = <&scpsys MT6895_POWER_DOMAIN_ISP_DIP1>;
	};

	disable-unused-pd-isp_ipe {
		compatible = "mediatek,scpsys-disable-unused";
		power-domains = <&scpsys MT6895_POWER_DOMAIN_ISP_IPE>;
	};

	disable-unused-pd-isp_vcore {
		compatible = "mediatek,scpsys-disable-unused";
		power-domains = <&scpsys MT6895_POWER_DOMAIN_ISP_VCORE>;
	};

	disable-unused-pd-vde0 {
		compatible = "mediatek,scpsys-disable-unused";
		power-domains = <&scpsys MT6895_POWER_DOMAIN_VDE0>;
	};

	disable-unused-pd-vde1 {
		compatible = "mediatek,scpsys-disable-unused";
		power-domains = <&scpsys MT6895_POWER_DOMAIN_VDE1>;
	};

	disable-unused-pd-ven0 {
		compatible = "mediatek,scpsys-disable-unused";
		power-domains = <&scpsys MT6895_POWER_DOMAIN_VEN0>;
	};

	disable-unused-pd-ven1 {
		compatible = "mediatek,scpsys-disable-unused";
		power-domains = <&scpsys MT6895_POWER_DOMAIN_VEN1>;
	};

	disable-unused-pd-cam_main {
		compatible = "mediatek,scpsys-disable-unused";
		power-domains = <&scpsys MT6895_POWER_DOMAIN_CAM_MAIN>;
	};

	disable-unused-pd-cam_mraw {
		compatible = "mediatek,scpsys-disable-unused";
		power-domains = <&scpsys MT6895_POWER_DOMAIN_CAM_MRAW>;
	};

	disable-unused-pd-cam_suba {
		compatible = "mediatek,scpsys-disable-unused";
		power-domains = <&scpsys MT6895_POWER_DOMAIN_CAM_SUBA>;
	};

	disable-unused-pd-cam_subb {
		compatible = "mediatek,scpsys-disable-unused";
		power-domains = <&scpsys MT6895_POWER_DOMAIN_CAM_SUBB>;
	};

	disable-unused-pd-cam_subc {
		compatible = "mediatek,scpsys-disable-unused";
		power-domains = <&scpsys MT6895_POWER_DOMAIN_CAM_SUBC>;
	};

	disable-unused-pd-cam_vcore {
		compatible = "mediatek,scpsys-disable-unused";
		power-domains = <&scpsys MT6895_POWER_DOMAIN_CAM_VCORE>;
	};

	disable-unused-pd-mdp0 {
		compatible = "mediatek,scpsys-disable-unused";
		power-domains = <&scpsys MT6895_POWER_DOMAIN_MDP0>;
	};

	disable-unused-pd-mdp1 {
		compatible = "mediatek,scpsys-disable-unused";
		power-domains = <&scpsys MT6895_POWER_DOMAIN_MDP1>;
	};

	disable-unused-pd-disp {
		compatible = "mediatek,scpsys-disable-unused";
		power-domains = <&scpsys MT6895_POWER_DOMAIN_DISP>;
	};

	disable-unused-pd-disp1 {
		compatible = "mediatek,scpsys-disable-unused";
		power-domains = <&scpsys MT6895_POWER_DOMAIN_DISP1>;
	};

	disable-unused-pd-mm_infra {
		compatible = "mediatek,scpsys-disable-unused";
		power-domains = <&scpsys MT6895_POWER_DOMAIN_MM_INFRA>;
	};

	disable-unused-pd-mm_proc_dormant {
		compatible = "mediatek,scpsys-disable-unused";
		power-domains = <&scpsys MT6895_POWER_DOMAIN_MM_PROC_DORMANT>;
	};

	disable-unused-pd-dp_tx {
		compatible = "mediatek,scpsys-disable-unused";
		power-domains = <&scpsys MT6895_POWER_DOMAIN_DP_TX>;
	};
};
